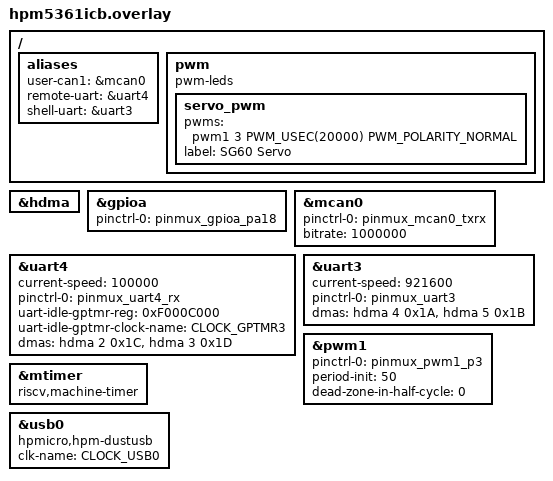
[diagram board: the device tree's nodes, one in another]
#include "dt-bindings/pinctrl/hpmicro-pinctrl-common.h"
#include <dt-bindings/clock/hpm5361-clocks.h>
#include <zephyr/dt-bindings/pwm/pwm.h>

/ {
    aliases {
        user-can1   = &mcan0;
        remote-uart = &uart4;
        shell-uart  = &uart3;
    };

    pwm {
        compatible = "pwm-leds";

        servo_pwm: servo_pwm {
            pwms = <&pwm1 3 PWM_USEC(20000) PWM_POLARITY_NORMAL>;
            label = "SG60 Servo";
            status = "okay";
        };
    };
};

&hdma {
    status = "okay";
};

&gpioa {
    pinctrl-0 = <&pinmux_gpioa_pa18>;
    pinctrl-names = "default";
    status = "okay";
};

&mcan0 {
    pinctrl-0 = <&pinmux_mcan0_txrx>;
    pinctrl-names = "default";
    bitrate = <1000000>;
    status = "okay";
};

&uart4 {
    current-speed = <100000>;
    pinctrl-0 = <&pinmux_uart4_rx>;
    pinctrl-names = "default";
    uart-idle-gptmr-reg = <0xF000C000>;
    uart-idle-gptmr-clock-name = <CLOCK_GPTMR3>;
    dmas = <&hdma 2 0x1C>, <&hdma 3 0x1D>;
    dma-names = "rx", "tx";
    status = "okay";
};

&uart3 {
    current-speed = <921600>;
    pinctrl-0 = <&pinmux_uart3>;
    pinctrl-names = "default";
    dmas = <&hdma 4 0x1A>, <&hdma 5 0x1B>;
    dma-names = "rx", "tx";
    status = "okay";
};

&pwm1 {
    pinctrl-0 = <&pinmux_pwm1_p3>;
    pinctrl-names = "default";
    period-init = <50>;
    dead-zone-in-half-cycle = <0>;
    status = "okay";
};

&mtimer {
    compatible = "riscv,machine-timer", "andestech,machine-timer";
    reg-names = "mtime", "mtimecmp";
};

dustusb_usb0: &usb0 {
    compatible = "hpmicro,hpm-dustusb";
    clk-name = <CLOCK_USB0>;
    status = "okay";
};
